# R7FA0E303 register map
Vendor: Renesas Electronics Corporation; Series: RA0; File version: 1.00.00
CPU: CM23 r1p0, little endian, no MPU, no FPU, VTOR, 2 interrupt priority bits, 64 interrupts
Registers are 16-bit, read-write, reset 0x0 unless marked. A register's access mark holds for its fields unless they carry their own. Offsets are from the block's base; [hi:lo] are bit positions; {n}, {i} and the like mark numbered series.

## PORT0 — Port 0 Control
Base 0x400A0000
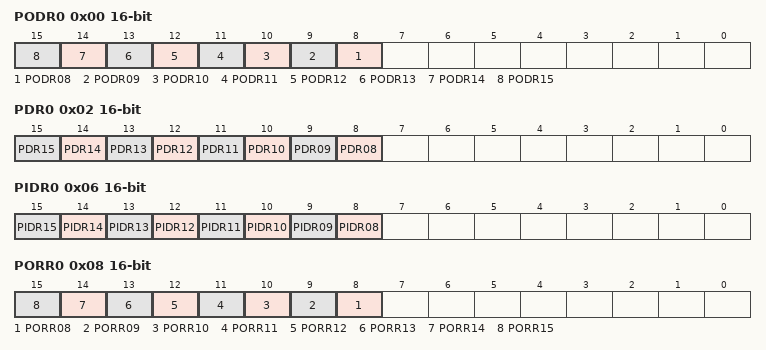
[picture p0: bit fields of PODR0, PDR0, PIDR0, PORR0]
0x00 PODR0 — Port 0 Output Data Register
  [all] fields
    0=Low output; 1=High output
  [n] PODR{n:02} (n=8..15) — P{n:03} Output Data
0x02 PDR0 — Port 0 Direction Register
  [all] fields
    0=Output 0; 1=Output 1
  [n] PDR{n:02} (n=8..15) — P{n:03} Direction
0x06 PIDR0 ro — Port 0 State Register
  [all] fields
    0=Low level; 1=High level
  [n] PIDR{n:02} (n=8..15) — P{n:03} State
0x08 PORR0 wo — Port 0 Output Reset Register
  [all] fields
    0=No effect on output; 1=Low output
  [n] PORR{n:02} (n=8..15) — P{n:03} Output Reset
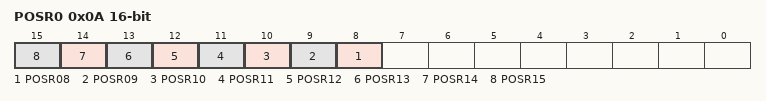
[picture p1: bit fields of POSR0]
0x0A POSR0 wo — Port 0 Output Set Register
  [all] fields
    0=No effect on output; 1=High output
  [n] POSR{n:02} (n=8..15) — P{n:03} Output Set

## PORT1 — Port 1 Control
Base 0x400A0020
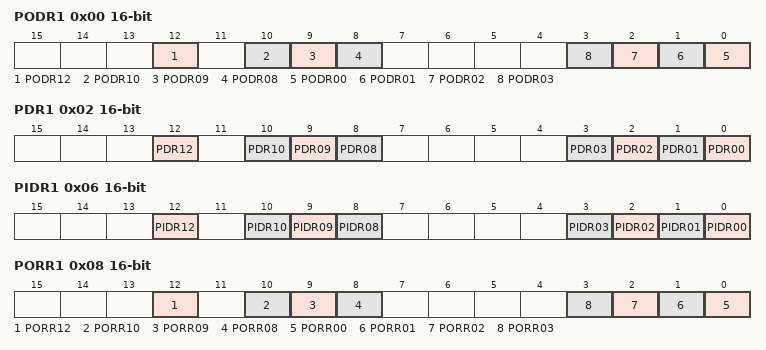
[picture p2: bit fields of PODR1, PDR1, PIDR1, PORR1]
0x00 PODR1 — Port 1 Output Data Register
  [all] fields
    0=Low output; 1=High output
  [12] PODR12 — P112 Output Data
  [10] PODR10 — P110 Output Data
  [9] PODR09 — P109 Output Data
  [8] PODR08 — P108 Output Data
  [n] PODR{n:02} (n=0..3) — P{n+100} Output Data
0x02 PDR1 — Port 1 Direction Register
  [all] fields
    0=Output 0; 1=Output 1
  [12] PDR12 — P112 Direction
  [10] PDR10 — P110 Direction
  [9] PDR09 — P109 Direction
  [8] PDR08 — P108 Direction
  [n] PDR{n:02} (n=0..3) — P{n+100} Direction
0x06 PIDR1 ro (reset mask 0xE8F3) — Port 1 State Register
  [all] fields
    0=Low level; 1=High level
  [12] PIDR12 — P112 State
  [10] PIDR10 — P110 State
  [9] PIDR09 — P109 State
  [8] PIDR08 — P108 State
  [n] PIDR{n:02} (n=0..3) — P{n+100} State
0x08 PORR1 wo — Port 1 Output Reset Register
  [all] fields
    0=No effect on output; 1=Low output
  [12] PORR12 — P112 Output Reset
  [10] PORR10 — P110 Output Reset
  [9] PORR09 — P109 Output Reset
  [8] PORR08 — P108 Output Reset
  [n] PORR{n:02} (n=0..3) — P{n+100} Output Reset
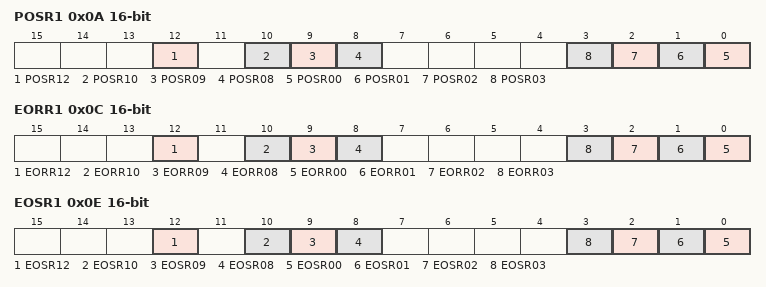
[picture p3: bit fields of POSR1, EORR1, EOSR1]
0x0A POSR1 wo — Port 1 Output Set Register
  [all] fields
    0=No effect on output; 1=High output
  [12] POSR12 — P112 Output Set
  [10] POSR10 — P110 Output Set
  [9] POSR09 — P109 Output Set
  [8] POSR08 — P108 Output Set
  [n] POSR{n:02} (n=0..3) — P{n+100} Output Set
0x0C EORR1 — Port 1 Event Output Reset Register
  [all] fields
    0=No effect on output; 1=Low output
  [12] EORR12 — P112 Event Output Reset
  [10] EORR10 — P110 Event Output Reset
  [9] EORR09 — P109 Event Output Reset
  [8] EORR08 — P108 Event Output Reset
  [n] EORR{n:02} (n=0..3) — P{n+100} Event Output Reset
0x0E EOSR1 — Port 1 Event Output Set Register
  [all] fields
    0=No effect on output; 1=High output
  [12] EOSR12 — P112 Event Output Set
  [10] EOSR10 — P110 Event Output Set
  [9] EOSR09 — P109 Event Output Set
  [8] EOSR08 — P108 Event Output Set
  [n] EOSR{n:02} (n=0..3) — P{n+100} Event Output Set

## PORT2 — Port 2 Control
Base 0x400A0040
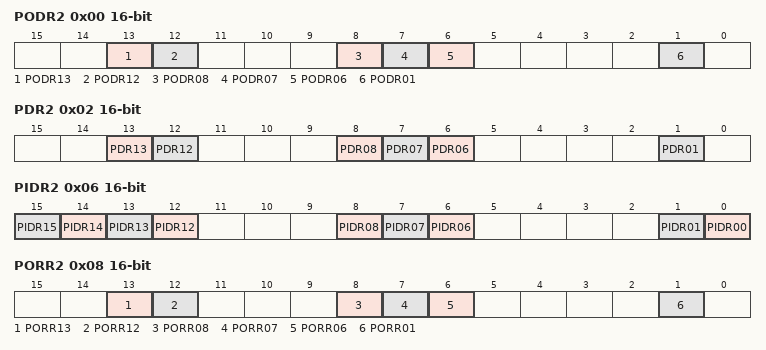
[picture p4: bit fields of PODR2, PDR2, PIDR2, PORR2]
0x00 PODR2 — Port 2 Output Data Register
  [all] fields
    0=Low output; 1=High output
  [13] PODR13 — P213 Output Data
  [12] PODR12 — P212 Output Data
  [8] PODR08 — P208 Output Data
  [7] PODR07 — P207 Output Data
  [6] PODR06 — P206 Output Data
  [1] PODR01 — P201 Output Data
0x02 PDR2 — Port 2 Direction Register
  [all] fields
    0=Output 0; 1=Output 1
  [13] PDR13 — P213 Direction
  [12] PDR12 — P212 Direction
  [8] PDR08 — P208 Direction
  [7] PDR07 — P207 Direction
  [6] PDR06 — P206 Direction
  [1] PDR01 — P201 Direction
0x06 PIDR2 ro (reset mask 0xE3C) — Port 2 State Register
  [all] fields
    0=Low level; 1=High level
  [n] PIDR{n} (n=12..15) — P{n+200} State
  [8] PIDR08 — P208 State
  [7] PIDR07 — P207 State
  [6] PIDR06 — P206 State
  [1] PIDR01 — P201 State
  [0] PIDR00 — P200 State
0x08 PORR2 wo — Port 2 Output Reset Register
  [all] fields
    0=No effect on output; 1=Low output
  [13] PORR13 — P213 Output Reset
  [12] PORR12 — P212 Output Reset
  [8] PORR08 — P208 Output Reset
  [7] PORR07 — P207 Output Reset
  [6] PORR06 — P206 Output Reset
  [1] PORR01 — P201 Output Reset
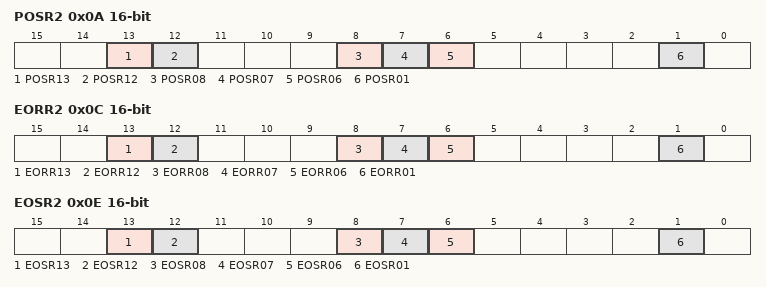
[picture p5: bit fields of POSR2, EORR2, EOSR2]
0x0A POSR2 wo — Port 2 Output Set Register
  [all] fields
    0=No effect on output; 1=High output
  [13] POSR13 — P213 Output Set
  [12] POSR12 — P212 Output Set
  [8] POSR08 — P208 Output Set
  [7] POSR07 — P207 Output Set
  [6] POSR06 — P206 Output Set
  [1] POSR01 — P201 Output Set
0x0C EORR2 — Port 2 Event Output Reset Register
  [all] fields
    0=No effect on output; 1=Low output
  [13] EORR13 — P213 Event Output Reset
  [12] EORR12 — P212 Event Output Reset
  [8] EORR08 — P208 Event Output Reset
  [7] EORR07 — P207 Event Output Reset
  [6] EORR06 — P206 Event Output Reset
  [1] EORR01 — P201 Event Output Reset
0x0E EOSR2 — Port 2 Event Output Set Register
  [all] fields
    0=No effect on output; 1=High output
  [13] EOSR13 — P213 Event Output Set
  [12] EOSR12 — P212 Event Output Set
  [8] EOSR08 — P208 Event Output Set
  [7] EOSR07 — P207 Event Output Set
  [6] EOSR06 — P206 Event Output Set
  [1] EOSR01 — P201 Event Output Set
